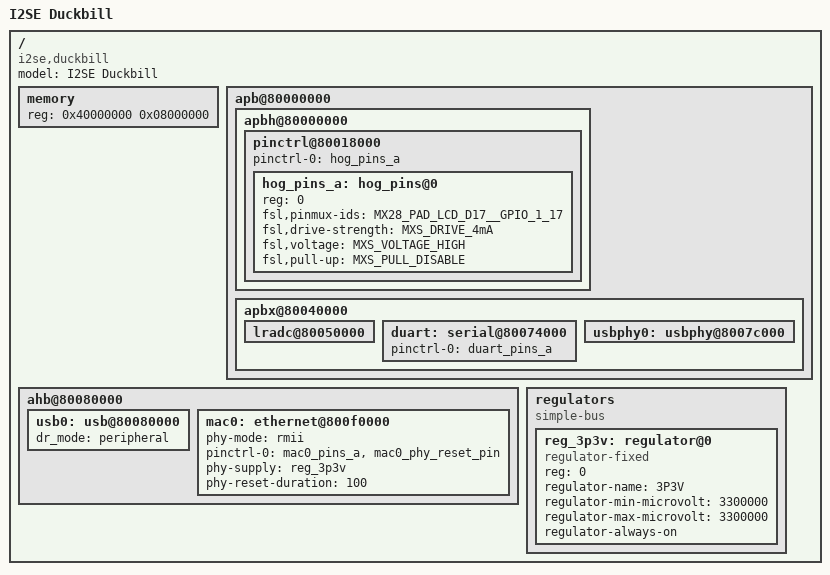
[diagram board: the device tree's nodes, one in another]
/*
 * Copyright (C) 2013-2014 Michael Heimpold <mhei@heimpold.de>
 * Copyright (C) 2015 I2SE GmbH <info@i2se.com>
 *
 * The code contained herein is licensed under the GNU General Public
 * License. You may obtain a copy of the GNU General Public License
 * Version 2 or later at the following locations:
 *
 * http://www.opensource.org/licenses/gpl-license.html
 * http://www.gnu.org/copyleft/gpl.html
 */

#include "imx28.dtsi"

/ {
	model = "I2SE Duckbill";
	compatible = "i2se,duckbill", "fsl,imx28";

	memory {
		reg = <0x40000000 0x08000000>;
	};

	apb@80000000 {
		apbh@80000000 {
			pinctrl@80018000 {
				pinctrl-names = "default";
				pinctrl-0 = <&hog_pins_a>;

				hog_pins_a: hog_pins@0 {
					reg = <0>;
					fsl,pinmux-ids = <
						MX28_PAD_LCD_D17__GPIO_1_17    /* Revision detection */
					>;
					fsl,drive-strength = <MXS_DRIVE_4mA>;
					fsl,voltage = <MXS_VOLTAGE_HIGH>;
					fsl,pull-up = <MXS_PULL_DISABLE>;
				};
			};
		};

		apbx@80040000 {
			lradc@80050000 {
				status = "okay";
			};

			duart: serial@80074000 {
				pinctrl-names = "default";
				pinctrl-0 = <&duart_pins_a>;
				status = "okay";
			};

			usbphy0: usbphy@8007c000 {
				status = "okay";
			};
		};
	};

	ahb@80080000 {
		usb0: usb@80080000 {
			status = "okay";
			dr_mode = "peripheral";
		};

		mac0: ethernet@800f0000 {
			phy-mode = "rmii";
			pinctrl-names = "default";
			pinctrl-0 = <&mac0_pins_a>, <&mac0_phy_reset_pin>;
			phy-supply = <&reg_3p3v>;
			phy-reset-duration = <100>;
			status = "okay";
		};
	};

	regulators {
		compatible = "simple-bus";
		#address-cells = <1>;
		#size-cells = <0>;

		reg_3p3v: regulator@0 {
			compatible = "regulator-fixed";
			reg = <0>;
			regulator-name = "3P3V";
			regulator-min-microvolt = <3300000>;
			regulator-max-microvolt = <3300000>;
			regulator-always-on;
		};
	};
};
